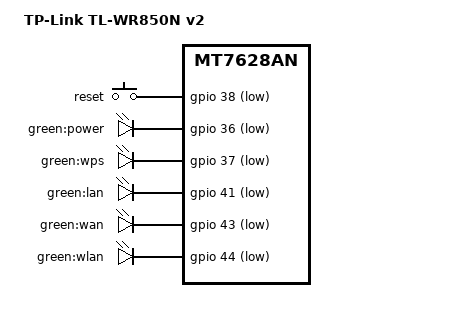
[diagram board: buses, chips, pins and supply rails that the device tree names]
// SPDX-License-Identifier: GPL-2.0-or-later OR MIT

#include "mt7628an_tplink_8m.dtsi"

/ {
	compatible = "tplink,tl-wr850n-v2", "mediatek,mt7628an-soc";
	model = "TP-Link TL-WR850N v2";

	aliases {
		led-boot = &led_power;
		led-failsafe = &led_power;
		led-running = &led_power;
		led-upgrade = &led_power;
	};

	keys {
		compatible = "gpio-keys";

		reset {
			label = "reset";
			gpios = <&gpio 38 GPIO_ACTIVE_LOW>;
			linux,code = <KEY_RESTART>;
		};
	};

	leds {
		compatible = "gpio-leds";

		led_power: power {
			label = "green:power";
			gpios = <&gpio 36 GPIO_ACTIVE_LOW>;
		};

		wps {
			label = "green:wps";
			gpios = <&gpio 37 GPIO_ACTIVE_LOW>;
		};

		lan {
			label = "green:lan";
			gpios = <&gpio 41 GPIO_ACTIVE_LOW>;
		};

		wan {
			label = "green:wan";
			gpios = <&gpio 43 GPIO_ACTIVE_LOW>;
		};

		wlan {
			label = "green:wlan";
			gpios = <&gpio 44 GPIO_ACTIVE_LOW>;
			linux,default-trigger = "phy0tpt";
		};
	};
};

&ehci {
	status = "disabled";
};

&ohci {
	status = "disabled";
};

&state_default {
	gpio {
		groups = "p0led_an", "p2led_an", "perst", "refclk", "wdt", "wled_an";
		function = "gpio";
	};
};

&esw {
	mediatek,portmap = <0x3e>;
};
